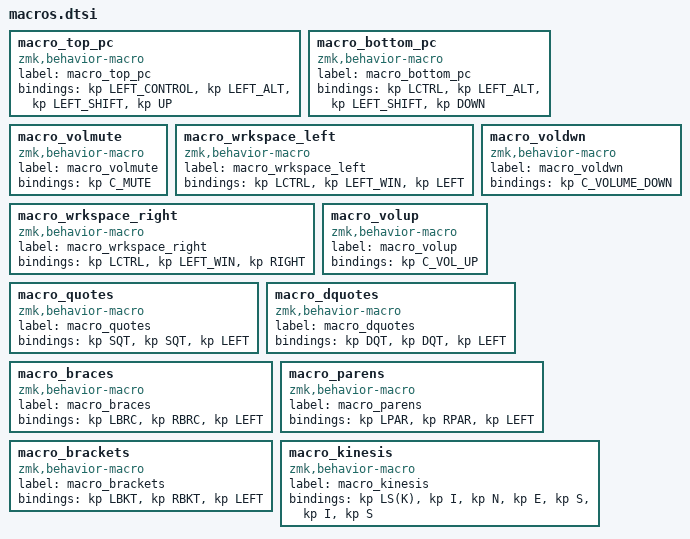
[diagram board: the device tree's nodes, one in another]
macro_top_pc: macro_top_pc{
compatible = "zmk,behavior-macro";
label = "macro_top_pc";
#binding-cells = <0>;
bindings = <&kp LEFT_CONTROL>, <&kp LEFT_ALT>, <&kp LEFT_SHIFT>, <&kp UP>;
};
macro_bottom_pc: macro_bottom_pc{
compatible = "zmk,behavior-macro";
label = "macro_bottom_pc";
#binding-cells = <0>;
bindings = <&kp LCTRL>, <&kp LEFT_ALT>, <&kp LEFT_SHIFT>, <&kp DOWN>;
};
macro_volmute: macro_volmute{
compatible = "zmk,behavior-macro";
label = "macro_volmute";
#binding-cells = <0>;
bindings = <&kp C_MUTE>;
};
macro_wrkspace_left: macro_wrkspace_left{
compatible = "zmk,behavior-macro";
label = "macro_wrkspace_left";
#binding-cells = <0>;
bindings = <&kp LCTRL>, <&kp LEFT_WIN>, <&kp LEFT>;
};
macro_wrkspace_right: macro_wrkspace_right{
compatible = "zmk,behavior-macro";
label = "macro_wrkspace_right";
#binding-cells = <0>;
bindings = <&kp LCTRL>, <&kp LEFT_WIN>, <&kp RIGHT>;
};
macro_voldwn: macro_voldwn{
compatible = "zmk,behavior-macro";
label = "macro_voldwn";
#binding-cells = <0>;
bindings = <&kp C_VOLUME_DOWN>;
};
macro_volup: macro_volup{
compatible = "zmk,behavior-macro";
label = "macro_volup";
#binding-cells = <0>;
bindings = <&kp C_VOL_UP>;
};
macro_quotes: macro_quotes{
compatible = "zmk,behavior-macro";
label = "macro_quotes";
#binding-cells = <0>;
bindings = <&kp SQT>, <&kp SQT>, <&kp LEFT>;
};
macro_dquotes: macro_dquotes{
compatible = "zmk,behavior-macro";
label = "macro_dquotes";
#binding-cells = <0>;
bindings = <&kp DQT>, <&kp DQT>, <&kp LEFT>;
};
macro_braces: macro_braces{
compatible = "zmk,behavior-macro";
label = "macro_braces";
#binding-cells = <0>;
bindings = <&kp LBRC>, <&kp RBRC>, <&kp LEFT>;
};
macro_parens: macro_parens{
compatible = "zmk,behavior-macro";
label = "macro_parens";
#binding-cells = <0>;
bindings = <&kp LPAR>, <&kp RPAR>, <&kp LEFT>;
};
macro_brackets: macro_brackets{
compatible = "zmk,behavior-macro";
label = "macro_brackets";
#binding-cells = <0>;
bindings = <&kp LBKT>, <&kp RBKT>, <&kp LEFT>;
};
macro_kinesis: macro_kinesis{
compatible = "zmk,behavior-macro";
label = "macro_kinesis";
#binding-cells = <0>;
bindings = <&kp LS(K)>, <&kp I>, <&kp N>, <&kp E>, <&kp S>, <&kp I>, <&kp S>;
};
